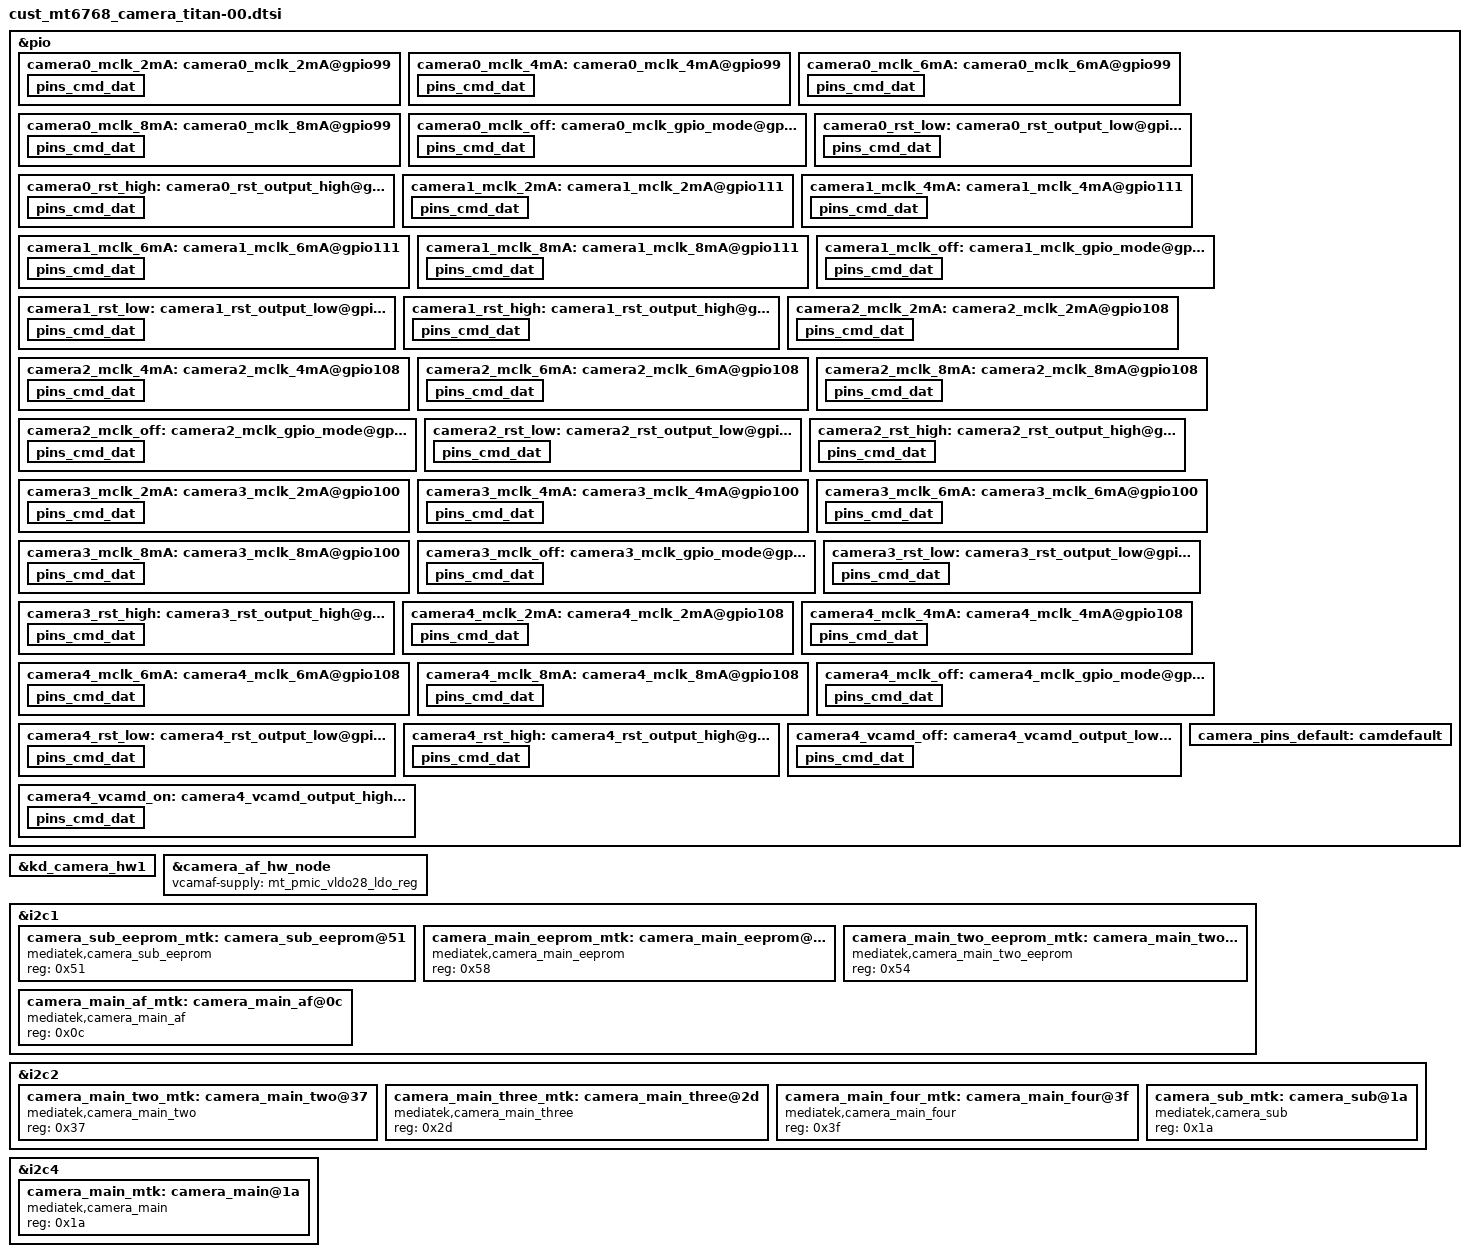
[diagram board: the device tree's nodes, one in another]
/*
 * Copyright (c) 2019 MediaTek Inc.
 *
 * This program is free software; you can redistribute it and/or modify
 * it under the terms of the GNU General Public License version 2 as
 * published by the Free Software Foundation.
 *
 * This program is distributed in the hope that it will be useful,
 * but WITHOUT ANY WARRANTY; without even the implied warranty of
 * MERCHANTABILITY or FITNESS FOR A PARTICULAR PURPOSE.  See the
 * GNU General Public License for more details.
 */

/*****  A31 Bringup Board  ********
 *    SW          :   HW   : Sensor
 * camera0(Wide)  : RCAM1  : IMX582
 * camera1(Front) : FCAM   : IMX616
 * camera2(UW)    : RCAM3  : 4HA
 * camera3(Depth) : RCAM2  : GC5035
 * camera4(Macro) : RCAM4  : GC5035
 **********************************/

/* CAMERA GPIO standardization */
&pio {
	/****************  Camera0  ***************/
	// MCLK
	camera0_mclk_2mA: camera0_mclk_2mA@gpio99 {
		pins_cmd_dat {
			pinmux = <PINMUX_GPIO99__FUNC_CMMCLK0>;
			drive-strength = <0>;
		};
	};
	camera0_mclk_4mA: camera0_mclk_4mA@gpio99 {
		pins_cmd_dat {
			pinmux = <PINMUX_GPIO99__FUNC_CMMCLK0>;
			drive-strength = <1>;
		};
	};
	camera0_mclk_6mA: camera0_mclk_6mA@gpio99 {
		pins_cmd_dat {
			pinmux = <PINMUX_GPIO99__FUNC_CMMCLK0>;
			drive-strength = <2>;
		};
	};
	camera0_mclk_8mA: camera0_mclk_8mA@gpio99 {
		pins_cmd_dat {
			pinmux = <PINMUX_GPIO99__FUNC_CMMCLK0>;
			drive-strength = <3>;
		};
	};
	camera0_mclk_off: camera0_mclk_gpio_mode@gpio99 {
		pins_cmd_dat {
			pinmux = <PINMUX_GPIO99__FUNC_GPIO99>;
			drive-strength = <1>;
		};
	};

	// Reset
	camera0_rst_low: camera0_rst_output_low@gpio102 {
		pins_cmd_dat {
			pinmux = <PINMUX_GPIO102__FUNC_GPIO102>;
			output-low;
		};
	};
	camera0_rst_high: camera0_rst_output_high@gpio102 {
		pins_cmd_dat {
			pinmux = <PINMUX_GPIO102__FUNC_GPIO102>;
			output-high;
		};
	};

	/****************  Camera1  ***************/
	// MCLK
	camera1_mclk_2mA: camera1_mclk_2mA@gpio111 {
		pins_cmd_dat {
			pinmux = <PINMUX_GPIO111__FUNC_CMMCLK3>;
			drive-strength = <0>;
		};
	};
	camera1_mclk_4mA: camera1_mclk_4mA@gpio111 {
		pins_cmd_dat {
			pinmux = <PINMUX_GPIO111__FUNC_CMMCLK3>;
			drive-strength = <1>;
		};
	};
	camera1_mclk_6mA: camera1_mclk_6mA@gpio111 {
		pins_cmd_dat {
			pinmux = <PINMUX_GPIO111__FUNC_CMMCLK3>;
			drive-strength = <2>;
		};
	};
	camera1_mclk_8mA: camera1_mclk_8mA@gpio111 {
		pins_cmd_dat {
			pinmux = <PINMUX_GPIO111__FUNC_CMMCLK3>;
			drive-strength = <3>;
		};
	};
	camera1_mclk_off: camera1_mclk_gpio_mode@gpio111 {
		pins_cmd_dat {
			pinmux = <PINMUX_GPIO111__FUNC_GPIO111>;
			drive-strength = <1>;
		};
	};

	// Reset
	camera1_rst_low: camera1_rst_output_low@gpio109 {
		pins_cmd_dat {
			pinmux = <PINMUX_GPIO109__FUNC_GPIO109>;
			output-low;
		};
	};
	camera1_rst_high: camera1_rst_output_high@gpio109 {
		pins_cmd_dat {
			pinmux = <PINMUX_GPIO109__FUNC_GPIO109>;
			output-high;
		};
	};

	/****************  Camera2  ***************/
	// MCLK
	camera2_mclk_2mA: camera2_mclk_2mA@gpio108 {
		pins_cmd_dat {
			pinmux = <PINMUX_GPIO108__FUNC_CMMCLK2>;
			drive-strength = <0>;
		};
	};
	camera2_mclk_4mA: camera2_mclk_4mA@gpio108 {
		pins_cmd_dat {
			pinmux = <PINMUX_GPIO108__FUNC_CMMCLK2>;
			drive-strength = <1>;
		};
	};
	camera2_mclk_6mA: camera2_mclk_6mA@gpio108 {
		pins_cmd_dat {
			pinmux = <PINMUX_GPIO108__FUNC_CMMCLK2>;
			drive-strength = <2>;
		};
	};
	camera2_mclk_8mA: camera2_mclk_8mA@gpio108 {
		pins_cmd_dat {
			pinmux = <PINMUX_GPIO108__FUNC_CMMCLK2>;
			drive-strength = <3>;
		};
	};
	camera2_mclk_off: camera2_mclk_gpio_mode@gpio108 {
		pins_cmd_dat {
			pinmux = <PINMUX_GPIO108__FUNC_GPIO108>;
			drive-strength = <1>;
		};
	};

	// Reset
	camera2_rst_low: camera2_rst_output_low@gpio27 {
		pins_cmd_dat {
			pinmux = <PINMUX_GPIO27__FUNC_GPIO27>;
			output-low;
		};
	};
	camera2_rst_high: camera2_rst_output_high@gpio27 {
		pins_cmd_dat {
			pinmux = <PINMUX_GPIO27__FUNC_GPIO27>;
			output-high;
		};
	};

	/****************  Camera3  ***************/
	// MCLK
	camera3_mclk_2mA: camera3_mclk_2mA@gpio100 {
		pins_cmd_dat {
			pinmux = <PINMUX_GPIO100__FUNC_CMMCLK1>;
			drive-strength = <0>;
		};
	};
	camera3_mclk_4mA: camera3_mclk_4mA@gpio100 {
		pins_cmd_dat {
			pinmux = <PINMUX_GPIO100__FUNC_CMMCLK1>;
			drive-strength = <1>;
		};
	};
	camera3_mclk_6mA: camera3_mclk_6mA@gpio100 {
		pins_cmd_dat {
			pinmux = <PINMUX_GPIO100__FUNC_CMMCLK1>;
			drive-strength = <2>;
		};
	};
	camera3_mclk_8mA: camera3_mclk_8mA@gpio100 {
		pins_cmd_dat {
			pinmux = <PINMUX_GPIO100__FUNC_CMMCLK1>;
			drive-strength = <3>;
		};
	};
	camera3_mclk_off: camera3_mclk_gpio_mode@gpio100 {
		pins_cmd_dat {
			pinmux = <PINMUX_GPIO100__FUNC_GPIO100>;
			drive-strength = <1>;
		};
	};

	// Reset
	camera3_rst_low: camera3_rst_output_low@gpio101 {
		pins_cmd_dat {
			pinmux = <PINMUX_GPIO101__FUNC_GPIO101>;
			output-low;
		};
	};
	camera3_rst_high: camera3_rst_output_high@gpio101 {
		pins_cmd_dat {
			pinmux = <PINMUX_GPIO101__FUNC_GPIO101>;
			output-high;
		};
	};

	/****************  Camera4  ***************/
	// MCLK
	camera4_mclk_2mA: camera4_mclk_2mA@gpio108 {
		pins_cmd_dat {
			pinmux = <PINMUX_GPIO108__FUNC_CMMCLK2>;
			drive-strength = <0>;
		};
	};
	camera4_mclk_4mA: camera4_mclk_4mA@gpio108 {
		pins_cmd_dat {
			pinmux = <PINMUX_GPIO108__FUNC_CMMCLK2>;
			drive-strength = <1>;
		};
	};
	camera4_mclk_6mA: camera4_mclk_6mA@gpio108 {
		pins_cmd_dat {
			pinmux = <PINMUX_GPIO108__FUNC_CMMCLK2>;
			drive-strength = <2>;
		};
	};
	camera4_mclk_8mA: camera4_mclk_8mA@gpio108 {
		pins_cmd_dat {
			pinmux = <PINMUX_GPIO108__FUNC_CMMCLK2>;
			drive-strength = <3>;
		};
	};
	camera4_mclk_off: camera4_mclk_gpio_mode@gpio108 {
		pins_cmd_dat {
			pinmux = <PINMUX_GPIO108__FUNC_GPIO108>;
			drive-strength = <1>;
		};
	};

	// Reset
	camera4_rst_low: camera4_rst_output_low@gpio112 {
		pins_cmd_dat {
			pinmux = <PINMUX_GPIO112__FUNC_GPIO112>;
			output-low;
		};
	};
	camera4_rst_high: camera4_rst_output_high@gpio112 {
		pins_cmd_dat {
			pinmux = <PINMUX_GPIO112__FUNC_GPIO112>;
			output-high;
		};
	};

	// DVDD
	camera4_vcamd_off: camera4_vcamd_output_low@gpio152 {
		pins_cmd_dat {
			pinmux = <PINMUX_GPIO152__FUNC_GPIO152>;
			output-low;
		};
	};
	camera4_vcamd_on: camera4_vcamd_output_high@gpio152 {
		pins_cmd_dat {
			pinmux = <PINMUX_GPIO152__FUNC_GPIO152>;
			output-high;
		};
	};

	/****************  default  ***************/
	camera_pins_default: camdefault {
	};
};

&kd_camera_hw1 {
	pinctrl-names = "default",
			"cam0_rst0", "cam0_rst1",
			"cam1_rst0", "cam1_rst1",
			"cam2_rst0", "cam2_rst1",
			"cam3_rst0", "cam3_rst1",
			"cam4_rst0", "cam4_rst1",
			"cam4_vcamd_on",
			"cam4_vcamd_off",
			"cam0_mclk_off",
			"cam0_mclk_2mA", "cam0_mclk_4mA",
			"cam0_mclk_6mA", "cam0_mclk_8mA",
			"cam1_mclk_off",
			"cam1_mclk_2mA", "cam1_mclk_4mA",
			"cam1_mclk_6mA", "cam1_mclk_8mA",
			"cam2_mclk_off",
			"cam2_mclk_2mA", "cam2_mclk_4mA",
			"cam2_mclk_6mA", "cam2_mclk_8mA",
			"cam3_mclk_off",
			"cam3_mclk_2mA", "cam3_mclk_4mA",
			"cam3_mclk_6mA", "cam3_mclk_8mA",
			"cam4_mclk_off",
			"cam4_mclk_2mA", "cam4_mclk_4mA",
			"cam4_mclk_6mA", "cam4_mclk_8mA";

	pinctrl-0 = <&camera_pins_default>;
	pinctrl-1 = <&camera0_rst_low>;
	pinctrl-2 = <&camera0_rst_high>;
	pinctrl-3 = <&camera1_rst_low>;
	pinctrl-4 = <&camera1_rst_high>;
	pinctrl-5 = <&camera2_rst_low>;
	pinctrl-6 = <&camera2_rst_high>;
	pinctrl-7 = <&camera3_rst_low>;
	pinctrl-8 = <&camera3_rst_high>;
	pinctrl-9 = <&camera4_rst_low>;
	pinctrl-10 = <&camera4_rst_high>;
	pinctrl-11 = <&camera4_vcamd_on>;
	pinctrl-12 = <&camera4_vcamd_off>;
	pinctrl-13 = <&camera0_mclk_off>;
	pinctrl-14 = <&camera0_mclk_2mA>;
	pinctrl-15 = <&camera0_mclk_4mA>;
	pinctrl-16 = <&camera0_mclk_6mA>;
	pinctrl-17 = <&camera0_mclk_8mA>;
	pinctrl-18 = <&camera1_mclk_off>;
	pinctrl-19 = <&camera1_mclk_2mA>;
	pinctrl-20 = <&camera1_mclk_4mA>;
	pinctrl-21 = <&camera1_mclk_6mA>;
	pinctrl-22 = <&camera1_mclk_8mA>;
	pinctrl-23 = <&camera2_mclk_off>;
	pinctrl-24 = <&camera2_mclk_2mA>;
	pinctrl-25 = <&camera2_mclk_4mA>;
	pinctrl-26 = <&camera2_mclk_6mA>;
	pinctrl-27 = <&camera2_mclk_8mA>;
	pinctrl-28 = <&camera3_mclk_off>;
	pinctrl-29 = <&camera3_mclk_2mA>;
	pinctrl-30 = <&camera3_mclk_4mA>;
	pinctrl-31 = <&camera3_mclk_6mA>;
	pinctrl-32 = <&camera3_mclk_8mA>;
	pinctrl-33 = <&camera4_mclk_off>;
	pinctrl-34 = <&camera4_mclk_2mA>;
	pinctrl-35 = <&camera4_mclk_4mA>;
	pinctrl-36 = <&camera4_mclk_6mA>;
	pinctrl-37 = <&camera4_mclk_8mA>;

	/********* Regulator setting **************/
	// Camera0
	cam0_vcama-supply = <&s2mpb03_l5>;
	cam0_vcamd-supply = <&s2mpb03_l1>;
	cam0_vcamio-supply = <&s2mpb03_l3>;
	cam0_vcamaf-supply = <&mt_pmic_vldo28_ldo_reg>;

	// Camera1
	cam1_vcama-supply = <&s2mpb03_l7>;
	cam1_vcamd-supply = <&s2mpb03_l2>;
	cam1_vcamio-supply = <&s2mpb03_l3>;

	// Camera2
	cam2_vcama-supply = <&mt_pmic_vcama1_ldo_reg>;
	cam2_vcamd-supply = <&s2mpb03_l4>;
	cam2_vcamio-supply = <&s2mpb03_l3>;

	// Camera3
	cam3_vcama-supply = <&s2mpb03_l6>;
	cam3_vcamd-supply = <&mt_pmic_vcamd_ldo_reg>;
	cam3_vcamio-supply = <&s2mpb03_l3>;

	// Camera4
	cam4_vcama-supply = <&mt_pmic_vcama2_ldo_reg>;
	cam4_vcamio-supply = <&s2mpb03_l3>;

	/***************** GPIO Expander **************/
	cam0_avdd2 = <&expander_gpios0 2 0>;

	/***************** MIPI Switch **************/
	mipi_switch_en = <&expander_gpios0 5 0>;
	mipi_switch_sel = <&expander_gpios0 11 0>;
	status = "okay";
};
/* CAMERA GPIO end */

/* CAMERA AF */

&camera_af_hw_node {
	vcamaf-supply = <&mt_pmic_vldo28_ldo_reg>;
	status = "okay";
};
/* CAMERA AF end */

/*************************
 *      Cmaera I2C
 *************************/

&i2c1 {
	#address-cells = <1>;
	#size-cells = <0>;
	clock-frequency = <400000>;
	mediatek,use-open-drain;
	camera_sub_eeprom_mtk:camera_sub_eeprom@51 {
		compatible = "mediatek,camera_sub_eeprom";
		reg = <0x51>;
		status = "okay";
	};

	camera_main_eeprom_mtk:camera_main_eeprom@58 {
		compatible = "mediatek,camera_main_eeprom";
		reg = <0x58>;
		status = "okay";
	};

	camera_main_two_eeprom_mtk:camera_main_two_eeprom@54 {
		compatible = "mediatek,camera_main_two_eeprom";
		reg = <0x54>;
		status = "okay";
	};

	camera_main_af_mtk:camera_main_af@0c {
		compatible = "mediatek,camera_main_af";
		reg = <0x0c>;
		status = "okay";
	};

};

&i2c2 {
	#address-cells = <1>;
	#size-cells = <0>;
	clock-frequency = <400000>;
	mediatek,use-open-drain;
	camera_main_two_mtk:camera_main_two@37 {
		compatible = "mediatek,camera_main_two";
		reg = <0x37>;
		status = "okay";
	};

	camera_main_three_mtk:camera_main_three@2d {
		compatible = "mediatek,camera_main_three";
		reg = <0x2d>;
		status = "okay";
	};

	camera_main_four_mtk:camera_main_four@3f {
		compatible = "mediatek,camera_main_four";
		reg = <0x3f>;
		status = "okay";
	};
	camera_sub_mtk:camera_sub@1a {
		compatible = "mediatek,camera_sub";
		reg = <0x1a>;
		status = "okay";
	};
};

&i2c4 {
	#address-cells = <1>;
	#size-cells = <0>;
	clock-frequency = <400000>;
	mediatek,use-open-drain;
	camera_main_mtk:camera_main@1a {
		compatible = "mediatek,camera_main";
		reg = <0x1a>;
		status = "okay";
	};

};
